# STM32WBA52 register map
File version: 0.1
CPU: CM33 r0p1, little endian, MPU, FPU, 4 interrupt priority bits
Registers are 32-bit, read-write, reset 0x0 unless marked. A register's access mark holds for its fields unless they carry their own. Offsets are from the block's base; [hi:lo] are bit positions.

## SYSCFG — System configuration controller
Base 0x46000400
Same registers: SEC_SYSCFG 0x56000400
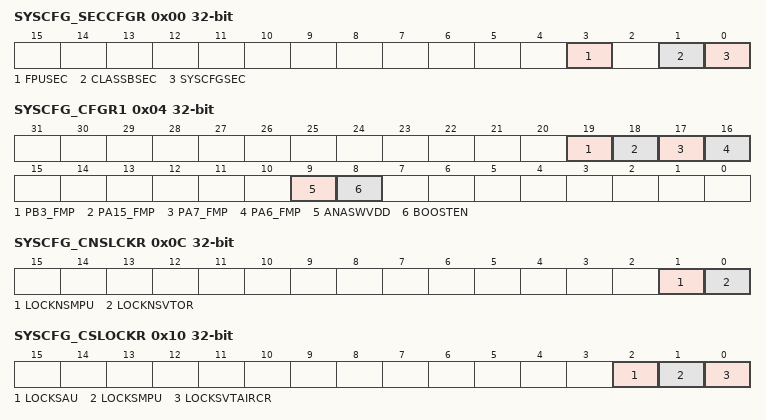
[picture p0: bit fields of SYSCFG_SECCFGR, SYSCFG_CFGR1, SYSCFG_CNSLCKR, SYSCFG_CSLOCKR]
0x00 SYSCFG_SECCFGR — SYSCFG secure configuration register
  [3] FPUSEC — FPU security
    0=SYSCFG_FPUIMR register can be read and written by secure and non-secure access; 1=SYSCFG_FPUIMR register can be read and written by secure access only
  [1] CLASSBSEC — Class B security
    0=SYSCFG_CFGR2 register can be read and written by secure and non-secure access; 1=SYSCFG_CFGR2 register can be read and written by secure access only
  [0] SYSCFGSEC — SYSCFG clock control, memory erase status and compensation cell registers security
    0=SYSCFG configuration clock in RCC registers, SYSCFG_MESR and SYSCFG_CCCSR, SYSCFG_CCVR and SYSCFG_CCCR can be read and written by secure and non-secure access; 1=SYSCFG configuration clock in RCC registers, SYSCFG_MESR and SYSCFG_CCCSR, SYSCFG_CCVR and SYSCFG_CCCR can be read and written by secure access only
0x04 SYSCFG_CFGR1 — SYSCFG configuration register 1
  [19] PB3_FMP — Fast-mode Plus drive capability activation on PB3 This bit can be read and written only with secure access if PB3 is secure in GPIOB. This bit enables the Fast-mode Plus drive mode for PB3 when PB3 is not used by I2C peripheral. This can be used to dive a LED for instance. Access can be protected by GPIOB SEC3.
    0=PB3 pin operates in standard mode when not used by I2C peripheral; 1=Fast-mode Plus mode is enabled on PAB3 pin and the GPIO speed control is bypassed
  [18] PA15_FMP — Fast-mode Plus drive capability activation on PA15 This bit can be read and written only with secure access if PA15 is secure in GPIOA. This bit enables the Fast-mode Plus drive mode for PA15 when PA15 is not used by I2C peripheral. This can be used to dive a LED for instance. Access can be protected by GPIOA SEC15.
    0=PA15 pin operates in standard mode when not used by I2C peripheral; 1=Fast-mode Plus mode is enabled on PA15 pin and the GPIO speed control is bypassed
  [17] PA7_FMP — Fast-mode Plus drive capability activation on PA7 This bit can be read and written only with secure access if PA7 is secure in GPIOA. This bit enables the Fast-mode Plus drive mode for PA7 when PA7 is not used by I2C peripheral. This can be used to dive a LED for instance. Access can be protected by GPIOA SEC7.
    0=PA7 pin operates in standard mode when not used by I2C peripheral; 1=Fast-mode Plus mode is enabled on PA7 pin and the GPIO speed control is bypassed
  [16] PA6_FMP — Fast-mode Plus drive capability activation on PA6 This bit can be read and written only with secure access if PA6 is secure in GPIOA. This bit enables the Fast-mode Plus drive mode for PA6 when PA6 is not used by I2C peripheral. This can be used to dive a LED for instance. Access can be protected by GPIOA SEC6.
    0=PA6 pin operates in standard mode when not used by I2C peripheral; 1=Fast-mode Plus mode is enabled on PA6 pin and the GPIO speed control is bypassed
  [9] ANASWVDD — GPIO analog switch control voltage selection Access can be protected by GTZC_TZSC ADC4SEC. Note: Refer to Table�121 for setting.
    0=I/O analog switches are supplied by V<sub>DDA</sub> or booster when booster is ON; 1=I/O analog switches are supplied by V<sub>DD</sub>
  [8] BOOSTEN — I/O analog switch voltage booster enable Access can be protected by GTZC_TZSC ADC4SEC. Note: Refer to Table�121 for setting.
    0=I/O analog switches are supplied by V<sub>DDA</sub> voltage; 1=I/O analog switches are supplied by a dedicated voltage booster (supplied by V<sub>DD</sub>)
0x08 SYSCFG_FPUIMR reset 0x3F — SYSCFG FPU interrupt mask register
  [5:0] FPU_IE — Floating point unit interrupts enable bits FPU_IE[5]: Inexact interrupt enable (interrupt disable at reset) FPU_IE[4]: Input abnormal interrupt enable FPU_IE[3]: Overflow interrupt enable FPU_IE[2]: Underflow interrupt enable FPU_IE[1]: Divide-by-zero interrupt enable FPU_IE[0]: Invalid operation Interrupt enable
0x0C SYSCFG_CNSLCKR — SYSCFG CPU non-secure lock register
  [1] LOCKNSMPU — Non-secure MPU registers lock This bit is set by software and cleared only by a system reset. When set, this bit disables write access to non-secure MPU_CTRL_NS, MPU_RNR_NS and MPU_RBAR_NS registers.
    0=Non-secure MPU registers write enabled; 1=Non-secure MPU registers write disabled
  [0] LOCKNSVTOR — VTOR_NS register lock This bit is set by software and cleared only by a system reset.
    0=VTOR_NS register write enabled; 1=VTOR_NS register write disabled
0x10 SYSCFG_CSLOCKR — SYSCFG CPU secure lock register
  [2] LOCKSAU — SAU registers lock This bit is set by software and cleared only by a system reset. When set, it disables write access to SAU_CTRL, SAU_RNR, SAU_RBAR and SAU_RLAR registers.
    0=SAU registers write enabled; 1=SAU registers write disabled
  [1] LOCKSMPU — Secure MPU registers lock This bit is set by software and cleared only by a system reset. When set, it disables write access to secure MPU_CTRL, MPU_RNR and MPU_RBAR registers.
    0=Secure MPU registers writes enabled; 1=Secure MPU registers writes disabled
  [0] LOCKSVTAIRCR — VTOR_S register and AIRCR register bits lock This bit is set by software and cleared only by a system reset. When set, it disables write access to VTOR_S register, PRIS and BFHFNMINS bits in the AIRCR register.
    0=VTOR_S register PRIS and BFHFNMINS bits in the AIRCR register write enabled; 1=VTOR_S register PRIS and BFHFNMINS bits in the AIRCR register write disabled
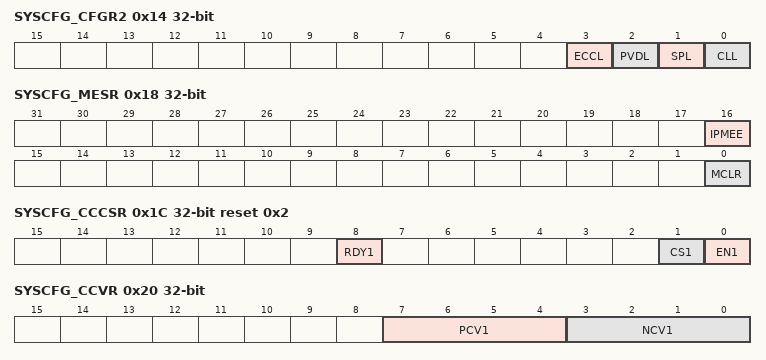
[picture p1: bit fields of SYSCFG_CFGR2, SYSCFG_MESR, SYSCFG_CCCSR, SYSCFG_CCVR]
0x14 SYSCFG_CFGR2 — SYSCFG configuration register 2
  [3] ECCL — ECC lock This bit is set by software and cleared only by a system reset. It can be used to enable and lock the Flash ECC double error signal connection to TIM1/16/17 break input.
    0=ECC double error disconnected from TIM1/16/17 break input; 1=ECC double error connected to TIM1/16/17 break input
  [2] PVDL — PVD lock enable bit This bit is set by software and cleared only by a system reset. It can be used to enable and lock the PVD connection to TIM1/16/17 break input, as well as the PVDE and PVDLS[2:0] in the PWR register.
    0=PVD interrupt disconnected from TIM1/16/17 break input. PVDE and PVDLS[2:0] bits can be programmed by the application.; 1=PVD interrupt connected to TIM1/16/17 break input. PVDE and PVDLS[2:0] bits are read only.
  [1] SPL — SRAM2 parity lock bit This bit is set by software and cleared only by a system reset. It can be used to enable and lock the SRAM2 parity error signal connection to TIM1/16/17 break inputs.
    0=SRAM2 parity error disconnected from TIM1/16/17 break inputs; 1=SRAM2 parity error connected to TIM1/16/17 break inputs
  [0] CLL — Cortex-M33 LOCKUP (hardfault) output enable This bit is set by software and cleared only by a system reset. It can be used to enable and lock the connection of Cortex-M33 LOCKUP (hardfault) output to TIM1/16/17 break input.
    0=Cortex-M33 LOCKUP output disconnected from TIM1/16/17 break inputs; 1=Cortex-M33 LOCKUP output connected to TIM1/16/17 break inputs
0x18 SYSCFG_MESR — SYSCFG memory erase status register
  [16] IPMEE — ICACHE and PKA SRAM erase status This bit is set by hardware when ICACHE and PKA SRAM erase is completed after potential tamper detection (refer to Section�75: Tamper and backup registers (TAMP) for more details). This bit is cleared by software by writing 1 to it.
    0=ICACHE and PKA SRAM erase ongoing if not yet cleared by software; 1=ICACHE and PKA SRAM erase done
  [0] MCLR — Device memories erase status This bit is set by hardware when SRAM2, ICACHE, PKA SRAM erase is completed after power-on reset or tamper detection (refer to Section�75: Tamper and backup registers (TAMP) for more details). This bit is not reset by system reset and is cleared by software by writing 1 to it.
    0=Memory erase ongoing if not yet cleared by software; 1=Memory erase done
0x1C SYSCFG_CCCSR access per field reset 0x2 — SYSCFG compensation cell control/status register
  [8] RDY1 ro — VDD I/Os compensation cell ready flag This bit provides the compensation cell status of the I/Os supplied by V<sub>DD</sub>. Note: The HSI16 clock is required for the compensation cell to work properly. The compensation cell ready bit (RDY1) is not set if the HSI16 clock is not enabled (HSION).
    0=VDD I/Os compensation cell not ready; 1=VDD I/Os compensation cell ready
  [1] CS1 rw — VDD I/Os code selection This bit selects the code to be applied for the compensation cell of the I/Os supplied by V<sub>DD</sub>.
    0=VDD I/Os code from the cell (available in the SYSCFG_CCVR); 1=VDD I/Os code from the SYSCFG compensation cell code register (SYSCFG_CCCR)
  [0] EN1 rw — VDD I/Os compensation cell enable This bit enables the compensation cell of the I/Os supplied by V<sub>DD</sub>.
    0=VDD I/Os compensation cell disabled; 1=VDD I/Os compensation cell enabled
0x20 SYSCFG_CCVR ro — SYSCFG compensation cell value register
  [7:4] PCV1 — PMOS compensation value of the I/Os supplied by V<sub>DD</sub> This value is provided by the cell and can be used by the CPU to compute an I/Os compensation cell code for PMOS transistors. This code is applied to the I/Os compensation cell when the CS1 bit of the SYSCFG_CCCSR is reset.
  [3:0] NCV1 — NMOS compensation value of the I/Os supplied by V<sub>DD</sub> This value is provided by the cell and can be used by the CPU to compute an I/Os compensation cell code for NMOS transistors. This code is applied to the I/Os compensation cell when the CS1 bit of the SYSCFG_CCCSR is reset.
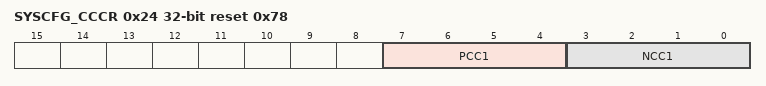
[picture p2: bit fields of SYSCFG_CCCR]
0x24 SYSCFG_CCCR reset 0x78 — SYSCFG compensation cell code register
  [7:4] PCC1 — PMOS compensation code of the I/Os supplied by V<sub>DD</sub> These bits are written by software to define an I/Os compensation cell code for PMOS transistors. This code is applied to the I/Os compensation cell when the CS1 bit of the SYSCFG_CCCSR is set.
  [3:0] NCC1 — NMOS compensation code of the I/Os supplied by V<sub>DD</sub> These bits are written by software to define an I/Os compensation cell code for NMOS transistors. This code is applied to the I/Os compensation cell when the CS1 bit of the SYSCFG_CCCSR is set.
0x2C SYSCFG_RSSCMDR — SYSCFG RSS command register
  [15:0] RSSCMD — RSS commands This field defines a command to be executed by the RSS.
